# NANO112AN_v1 register map
File version: 1.0
Registers are 32-bit, read-write, reset 0x0 unless marked. A register's access mark holds for its fields unless they carry their own. Offsets are from the block's base; [hi:lo] are bit positions; {n}, {i} and the like mark numbered series; 'fields as' and 'values as' point back to an identical list.

## GCR — GCR Register Map
Base 0x50000000
0x00 PDID ro reset 0x110000 (reset mask 0xFFFF0000) — Part Device Identification Number Register
  [31:0] PDID — Part Device ID. This register reflects device part number code. Software can read this register to identify which device is used.
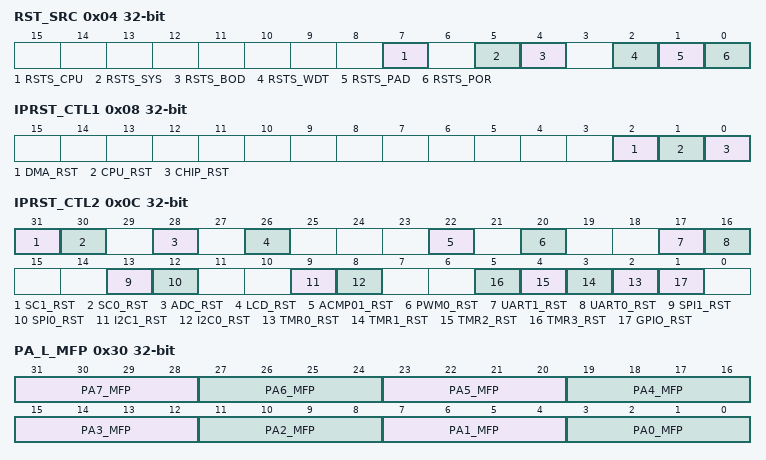
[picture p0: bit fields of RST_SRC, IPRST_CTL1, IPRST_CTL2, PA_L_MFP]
0x04 RST_SRC (reset mask 0xFFFFFF00) — System Reset Source Register
  [7] RSTS_CPU — The RSTS_CPU Flag Is Set by Hardware If Software Writes CPU_RST (IPRST_CTL1[1]) "1" to Rest Cortex-m0 Core and Flash Memory Controller (FMC). Note: This bit is cleared by writing 1 to it.
    0=No reset from CPU; 1=Cortex-M0 core and FMC are reset by software setting CPU_RST to 1
  [5] RSTS_SYS — The RSTS_SYS Flag Is Set by the "Reset Signal" From the Cortex_M0 Kernel to Indicate the Previous Reset Source. Note: This bit is cleared by writing 1 to it.
    0=No reset from Cortex_M0; 1=Cortex_M0 had issued the reset signal to reset the system by writing 1 to the bit SYSRESTREQ(AIRCR[2], Application Interrupt and Reset Control Register) in system control registers of Cortex_M0 kernel
  [4] RSTS_BOD — The RSTS_BOD Flag Is Set by the "Reset Signal" From the Brown-out-detected Module to Indicate the Previous Reset Source. Note: This bit is cleared by writing 1 to it.
    0=No reset from BOD; 1=Brown-out-Detected module had issued the reset signal to reset the system
  [2] RSTS_WDT — The RSTS_WDT Flag Is Set by the "Reset Signal" From the Watchdog Timer Module to Indicate the Previous Reset Source. Note: This bit is cleared by writing 1 to it.
    0=No reset from Watchdog Timer; 1=The Watchdog Timer module had issued the reset signal to reset the system
  [1] RSTS_PAD — The RSTS_PAD Flag Is Set by the "Reset Signal" From the /RESET Pin or Power Related Reset Sources to Indicate the Previous Reset Source. Note: This bit is cleared by writing 1 to it.
    0=No reset from nRESET pin; 1=The /RESET pin had issued the reset signal to reset the system
  [0] RSTS_POR — The RSTS_POR Flag Is Set by the "Reset Signal" From the Power-on Reset (POR) Module or Bit CHIP_RST (IPRSTC1[0]) to Indicate the Previous Reset Source. Note: This bit is cleared by writing 1 to it.
    0=No reset from POR or CHIP_RST; 1=Power-on Reset (POR) or CHIP_RST had issued the reset signal to reset the system
0x08 IPRST_CTL1 — Peripheral Reset Control Resister1
  [2] DMA_RST — DMA Controller Reset. This is a protected register. Please refer to open lock sequence to program it. Set this bit "1" will generate a reset signal to the DMA. SW needs to set this bit to low to release reset signal.
    0=Normal operation; 1=DMA IP reset
  [1] CPU_RST — Cortex-m0 Core One-shot Reset. This is a protected register. Please refer to open lock sequence to program it. Setting this bit will only reset the Cortex-M0 core and Flash Memory Controller (FMC), and this bit will automatically return to "0" after the 2 clock cycles
    0=Normal; 1=Reset Cortex-M0 core
  [0] CHIP_RST — Chip One-shot Reset. This is a protected register. Please refer to open lock sequence to program it. Setting this bit will reset the whole chip, including Cortex-M0 core and all peripherals like power-on reset and this bit will automatically return to "0" after the 2 clock cycles. The chip setting from flash will be also reloaded when chip one shot reset. Note: In the following conditions, chip setting from flash will be reloaded. Power-on Reset. Brown-out-Detected Reset. Low level on the nRESET pin. Set IPRST_CTL1[CHIP_RST]
    0=Normal; 1=Reset chip
0x0C IPRST_CTL2 — Peripheral Reset Control Resister2
  [31] SC1_RST — SmartCard1 Controller Reset
    0=SmartCard module normal operation; 1=SmartCard module reset
  [30] SC0_RST — SmartCard 0 Controller Reset
    values as SC1_RST
  [28] ADC_RST — ADC Controller Reset
    0=ADC module normal operation; 1=ADC module reset
  [26] LCD_RST — LCD Controller Reset
    0=LCD module normal operation; 1=LCD module reset
  [22] ACMP01_RST — Comparator Controller Reset
    0=Comparator module normal operation; 1=Comparator module reset
  [20] PWM0_RST — PWM0 Controller Reset
    0=PWM0 module normal operation; 1=PWM0 module reset
  [17] UART1_RST — UART1 Controller Reset
    0=UART1 module normal operation; 1=UART1 module reset
  [16] UART0_RST — UART0 Controller Reset
    0=UART0 module normal operation; 1=UART0 module reset
  [13] SPI1_RST — SPI1 Controller Reset
    0=SPI1 module normal operation; 1=SPI1 module reset
  [12] SPI0_RST — SPI0 Controller Reset
    0=SPI0 module normal operation; 1=SPI0 module reset
  [9] I2C1_RST — I2C1 Controller Reset
    0=I2C1 module normal operation; 1=I2C1 module reset
  [8] I2C0_RST — I2C0 Controller Reset
    0=I2C0 module normal operation; 1=I2C0 module reset
  [n+2] TMR{n}_RST (n=0..3) — Timer{n} Controller Reset
    0=Timer{n} module normal operation; 1=Timer{n} module reset
  [1] GPIO_RST — GPIO Controller Reset
    0=GPIO module normal operation; 1=GPIO module reset
0x20 TEMPCTL — Temperature Sensor Control Register
  [0] VTEMP_EN — Temperature Sensor Enable Control
    0=Temperature sensor function Disabled (default); 1=Temperature sensor function Enabled
0x30 PA_L_MFP — Port A Low Byte Multiple Function Control Register
  [31:28] PA7_MFP — PA.7 Pin Function Selection
  [27:24] PA6_MFP — PA.6 Pin Function Selection
  [23:20] PA5_MFP — PA.5 Pin Function Selection
  [19:16] PA4_MFP — PA.4 Pin Function Selection
  [15:12] PA3_MFP — PA.3 Pin Function Selection
  [11:8] PA2_MFP — PA.2 Pin Function Selection
  [7:4] PA1_MFP — PA.1 Pin Function Selection
  [3:0] PA0_MFP — PA.0 Pin Function Selection
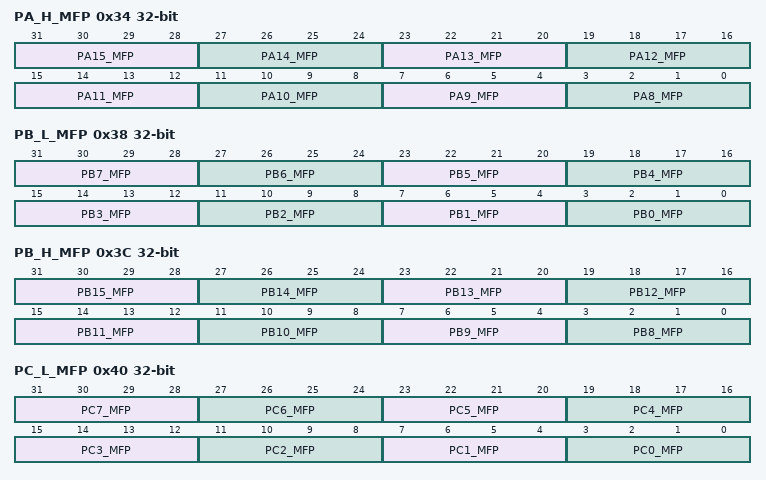
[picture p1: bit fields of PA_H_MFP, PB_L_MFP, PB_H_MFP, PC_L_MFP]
0x34 PA_H_MFP — Port A High Byte Multiple Function Control Register
  [31:28] PA15_MFP — PA.15 Pin Function Selection
  [27:24] PA14_MFP — PA.14 Pin Function Selection
  [23:20] PA13_MFP — PA.13 Pin Function Selection
  [19:16] PA12_MFP — PA.12 Pin Function Selection
  [15:12] PA11_MFP — PA.11 Pin Function Selection
  [11:8] PA10_MFP — PA.10 Pin Function Selection
  [7:4] PA9_MFP — PA.9 Pin Function Selection
  [3:0] PA8_MFP — PA.8 Pin Function Selection
0x38 PB_L_MFP — Port B Low Byte Multiple Function Control Register
  [31:28] PB7_MFP — PB.7 Pin Function Selection
  [27:24] PB6_MFP — PB.6 Pin Function Selection
  [23:20] PB5_MFP — PB.5 Pin Function Selection
  [19:16] PB4_MFP — PB.4 Pin Function Selection
  [15:12] PB3_MFP — PB.3 Pin Function Selection
  [11:8] PB2_MFP — PB.2 Pin Function Selection
  [7:4] PB1_MFP — PB.1 Pin Function Selection
  [3:0] PB0_MFP — PB.0 Pin Function Selection
0x3C PB_H_MFP — Port B High Byte Multiple Function Control Register
  [31:28] PB15_MFP — PB.15 Pin Function Selection
  [27:24] PB14_MFP — PB.14 Pin Function Selection
  [23:20] PB13_MFP — PB.13 Pin Function Selection
  [19:16] PB12_MFP — PB.12 Pin Function Selection
  [15:12] PB11_MFP — PB.11 Pin Function Selection
  [11:8] PB10_MFP — PB.10 Pin Function Selection
  [7:4] PB9_MFP — PB.9 Pin Function Selection
  [3:0] PB8_MFP — PB.8 Pin Function Selection
0x40 PC_L_MFP — Port C Low Byte Multiple Function Control Register
  [31:28] PC7_MFP — PC.7 Pin Function Selection
  [27:24] PC6_MFP — PC.6 Pin Fuction Selection
  [23:20] PC5_MFP — PC.5 Pin Function Selection
  [19:16] PC4_MFP — PC.4 Pin Function Selection
  [15:12] PC3_MFP — PC.3 Pin Function Selection
  [11:8] PC2_MFP — PC.2 Pin Function Selection
  [7:4] PC1_MFP — PC.1 Pin Function Selection
  [3:0] PC0_MFP — PC.0 Pin Function Selection
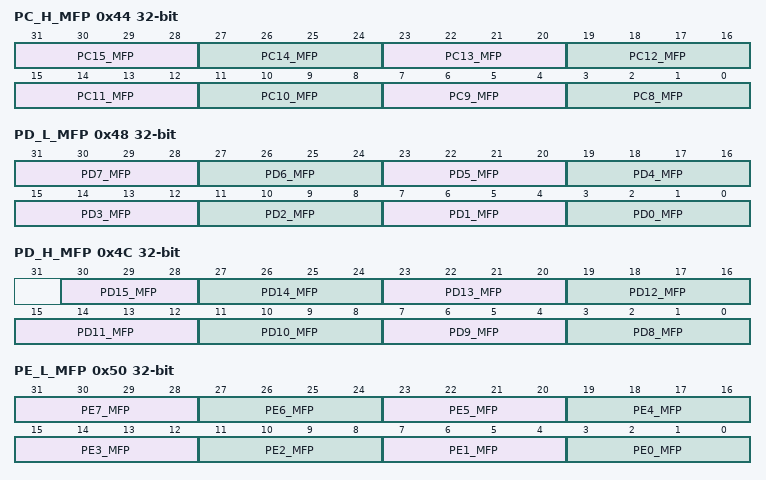
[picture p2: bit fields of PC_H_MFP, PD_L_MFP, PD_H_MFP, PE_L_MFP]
0x44 PC_H_MFP — Port C High Byte Multiple Function Control Register
  [31:28] PC15_MFP — PC.15 Pin Function Selection
  [27:24] PC14_MFP — PC.14 Pin Function Selection
  [23:20] PC13_MFP — PC.13 Pin Function Selection
  [19:16] PC12_MFP — PC.12 Pin Function Selection
  [15:12] PC11_MFP — PC.11 Pin Function Selection
  [11:8] PC10_MFP — PC.10 Pin Function Selection
  [7:4] PC9_MFP — PC.9 Pin Function Selection
  [3:0] PC8_MFP — PC.8 Pin Function Selection
0x48 PD_L_MFP — Port D Low Byte Multiple Function Control Register
  [31:28] PD7_MFP — PD.7 Pin Function Selection
  [27:24] PD6_MFP — PD.6 Pin Function Selection
  [23:20] PD5_MFP — PD.5 Pin Function Selection
  [19:16] PD4_MFP — PD.4 Pin Function Selection
  [15:12] PD3_MFP — PD.3 Pin Function Selection
  [11:8] PD2_MFP — PD.2 Pin Function Selection
  [7:4] PD1_MFP — PD.1 Pin Function Selection
  [3:0] PD0_MFP — PD.0 Pin Function Selection
0x4C PD_H_MFP — Port D High Byte Multiple Function Control Register
  [30:28] PD15_MFP — PD.15 Pin Function Selection
  [27:24] PD14_MFP — PD.14 Pin Function Selection
  [23:20] PD13_MFP — PD.13 Pin Function Selection
  [19:16] PD12_MFP — PD.12 Pin Function Selection
  [15:12] PD11_MFP — PD.11 Pin Function Selection
  [11:8] PD10_MFP — PD.10 Pin Function Selection
  [7:4] PD9_MFP — PD.9 Pin Function Selection
  [3:0] PD8_MFP — PD.8 Pin Function Selection
0x50 PE_L_MFP — Port E Low Byte Multiple Function Control Register
  [31:28] PE7_MFP — PE.7 Pin Function Selection
  [27:24] PE6_MFP — PE.6 Pin Function Selection
  [23:20] PE5_MFP — PE.5 Pin Function Selection
  [19:16] PE4_MFP — PE.4 Pin Function Selection
  [15:12] PE3_MFP — PE.3 Pin Function Selection
  [11:8] PE2_MFP — PE.2 Pin Function Selection
  [7:4] PE1_MFP — PE.1 Pin Function Selection
  [3:0] PE0_MFP — PE.0 Pin Function Selection
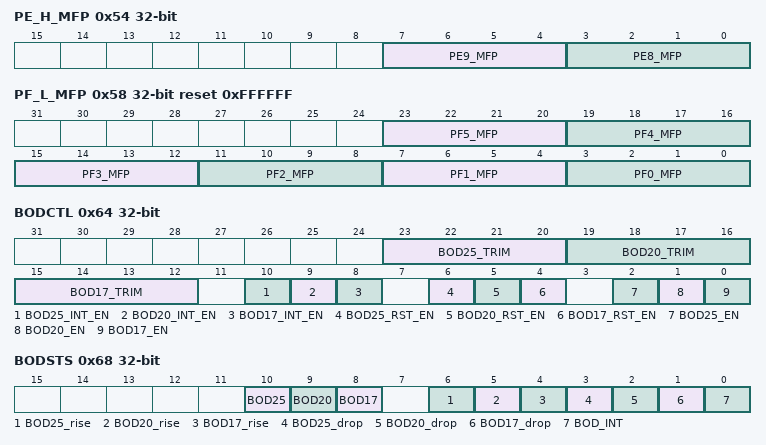
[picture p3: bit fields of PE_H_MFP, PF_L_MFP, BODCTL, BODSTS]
0x54 PE_H_MFP — Port E High Byte Multiple Function Control Register
  [7:4] PE9_MFP — PE.9 Pin Function Selection
  [3:0] PE8_MFP — PE.8 Pin Function Selection
0x58 PF_L_MFP reset 0xFFFFFF — Port F Low Byte Multiple Function Control Register
  [23:20] PF5_MFP — PF.5 Pin Function Selection
  [19:16] PF4_MFP — PF.4 Pin Function Selection
  [15:12] PF3_MFP — PF.3 Pin Function Selection
  [11:8] PF2_MFP — PF.2 Pin Function Selection
  [7:4] PF1_MFP — PF.1 Pin Function Selection
  [3:0] PF0_MFP — PF.0 Pin Function Selection
0x60 PORCTL — Power-On-reset Controller Register
  [15:0] POR_DIS_CODE — Power-on Reset Enable Control. This is a protected register. Please refer to open lock sequence to program it. When powered on, the POR circuit generates a reset signal to reset the whole chip function, but noise on the power may cause the POR active again. If setting the POR_DIS_CODE to 0x5AA5, the POR reset function will be disabled and the POR function will be active again when POR_DIS_CODE is set to another value or POR_DIS_CODE is reset by chip other reset functions, including: /RESET, Watchdog Timer reset, BOD reset, ICE reset command and the software-chip reset function
0x64 BODCTL (reset mask 0xFF000F00) — Brown-out Detector Controller Register
  [23:20] BOD25_TRIM — BOD 2.5 TRIM Value. This is a protected register. Please refer to open lock sequence to program it. This value is used to control BOD25 detect voltage level, nominal 2.5 V. Higher trim value, higher detection voltage.
  [19:16] BOD20_TRIM — BOD 2.0 TRIM Value. This is a protected register. Please refer to open lock sequence to program it. This value is used to control BOD20 detect voltage level, nominal 2.0 V. Higher trim value, higher detection voltage.
  [15:12] BOD17_TRIM — BOD 1.7 TRIM Value. This is a protected register. Please refer to open lock sequence to program it. This value is used to control BOD17 detect voltage level, nominal 1.7 V. Higher trim value, higher detection voltage.
  [10] BOD25_INT_EN — BOD 2.5 V Interrupt Enable Control. This is a protected register. Please refer to open lock sequence to program it.
    0=Interrupt does not issue when BOD25 occurs; 1=Interrupt issues when BOD25 occurs
  [9] BOD20_INT_EN — BOD 2.0 V Interrupt Enable Control
    0=Interrupt does not issue when BOD20 occurs; 1=Interrupt issues when BOD20 occurs
  [8] BOD17_INT_EN — BOD 1.7 V Interrupt Enable Control. This is a protected register. Please refer to open lock sequence to program it.
    0=Interrupt does not issue when BOD17 occurs; 1=Interrupt issues when BOD17 occurs
  [6] BOD25_RST_EN — BOD 2.5 V Reset Enable Control. This is a protected register. Please refer to open lock sequence to program it. The default value is set by flash controller user configuration register config0 bit[20:19]
    0=Reset does not issue when BOD25 occurs; 1=Reset issues when BOD25 occurs
  [5] BOD20_RST_EN — BOD 2.0 V Reset Enable Control. This is a protected register. Please refer to open lock sequence to program it. The default value is set by flash controller user configuration register config0 bit[20:19]
    0=Reset does not issue when BOD20 occurs; 1=Reset issues when BOD20 occurs
  [4] BOD17_RST_EN — BOD 1.7 V Reset Enable Control
    0=Reset does not issue when BOD17 occurs; 1=Reset issues when BOD17 occurs
  [2] BOD25_EN — Brown-out Detector 2.5 V Function Enable Control. This is a protected register. Please refer to open lock sequence to program it.
    0=Brown-out Detector 2.5 V function Disabled; 1=Brown-out Detector 2.5 V function Enabled
  [1] BOD20_EN — Brown-out Detector 2.0 V Function Enable Control. This is a protected register. Please refer to open lock sequence to program it. BOD20_EN is default on. If SW disables it, Brown-out Detector 2.0 V function is not disabled until chip enters Power-down mode. If system is not in Power-down mode, BOD20_EN will be enabled by hardware automatically.
    0=Brown-out Detector 2.0 V function Disabled; 1=Brown-out Detector 2.0 V function Enabled
  [0] BOD17_EN — Brown-out Detector 1.7V Function Enable Control
    0=Brown-out Detector 1.7V function Disabled; 1=Brown-out Detector 1.7V function Enabled
0x68 BODSTS ro — Brown-out Detector Status Register
  [10] BOD25 — Brown-out Detector 2.5V Status. This bit reflects the BOD25 status. BOD25 is high if detected voltage is higher than 2.5 V. BOD25 is low if detected voltage is lower than 2.5 V. Note: This bit is ready-only.
  [9] BOD20 — Brown-out Detector 2.0V Status. This bit reflects the BOD20 status. BOD20 is high if detected voltage is higher than 2.0 V. BOD20 is low if detected voltage is lower than 2.0 V. Note: This bit is ready-only.
  [8] BOD17 — Brown-out Detector 1.7V Status. This bit reflects the BOD17 status. BOD17 is high if detected voltage is higher than 1.7 V. BOD17 is low if detected voltage is lower than 1.7 V. Note: This bit is ready-only.
  [6] BOD25_rise — Brown-out Detector Higher Than 2.5V Status. Setting BOD25_rise high means once the detected voltage is higher than target detected voltage setting (2.5V). Software can write 1 to clear BOD25_rise.
  [5] BOD20_rise — Brown-out Detector Higher Than 2.0V Status. Setting BOD20_rise high means once the detected voltage is higher than target detected voltage setting (2.0V). Software can write 1 to clear BOD20_rise
  [4] BOD17_rise — Brown-out Detector Higher Than 1.7V Status. Setting BOD17_rise high means once the detected voltage is higher than target detected voltage setting (1.7V). Software can write 1 to clear BOD17_rise
  [3] BOD25_drop — Brown-out Detector Lower Than 2.5V Status. Setting BOD25_drop high means once the detected voltage is lower than target detected voltage setting (2.5V). Software can write 1 to clear BOD25_drop
  [2] BOD20_drop — Brown-out Detector Lower Than 2.0V Status. Setting BOD20_drop high means once the detected voltage is lower than target detected voltage setting (2.0V). Software can write 1 to clear BOD20_drop
  [1] BOD17_drop — Brown-out Detector Lower Than 1.7V Status. Setting BOD17_drop high means once the detected voltage is lower than target detected voltage setting (1.7V). Software can write 1 to clear BOD17_drop
  [0] BOD_INT — Brown-out Detector Interrupt Status. This bit is cleared by writing 1 to it.
    0=Brown-out Detector does not detect any voltage drift at VDD down through or up through the target detected voltage after interrupt is enabled; 1=When Brown-out Detector detects the VDD is dropped down through the target detected voltage or the VDD is raised up through the target detected voltage and Brown-out interrupt is enabled, this bit will be set to 1
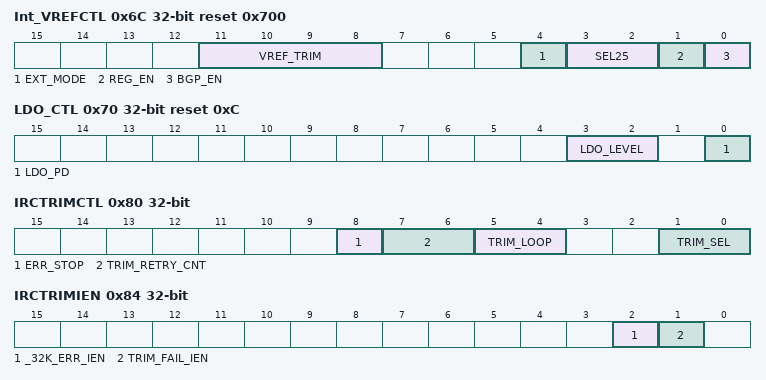
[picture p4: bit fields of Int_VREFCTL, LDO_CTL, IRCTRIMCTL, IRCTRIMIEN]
0x6C Int_VREFCTL reset 0x700 — Internal Voltage Reference Control Register
  [11:8] VREF_TRIM — Internal Voltage Reference Trim
  [4] EXT_MODE — Regulator External Mode. This is a protected register. Please refer to open lock sequence to program it. Users can output regulator output voltage in VREF pin if EXT_MODE is high.
    0=No connection with external VREF pin; 1=Connet to external VREF pin. Connect a 1uF to 10uF capacitor to AVSS will let internal voltage reference be more stable
  [3:2] SEL25 — Regulator Output Voltage Selection. Select internal reference voltage level. This is a protected register. Please refer to open lock sequence to program it.
    0=1.5V; 1=1.8V; 2=2.5V; 3=2.5V
  [1] REG_EN — Regulator Enable Control. Enable internal 1.5, 1.8V or 2.5V reference voltage. This is a protected register. Please refer to open lock sequence to program it.
    0=Disabled; 1=Enabled
  [0] BGP_EN — Band-gap Enable Control. This is a protected register. Please refer to open lock sequence to program it. Band-gap is the reference voltage of internal reference voltage. User must enable band-gap if want to enable internal 1.5, 1.8V or 2.5V reference voltage.
    0=Disabled; 1=Enabled
0x70 LDO_CTL reset 0xC — LDO Control Register
  [3:2] LDO_LEVEL — LDO Output Voltage Select. This is a protected register. Please refer to open lock sequence to program it.
    0=Reseved; 1=1.6V; 2=1.8V; 3=1.8V
  [0] LDO_PD — LDO Power Off. This is a protected register. Please refer to open lock sequence to program it. Set this bit high will off LDO and cause Chip in unexpected state. User must keep this bit low.
    0=LDO Enabled; 1=LDO Disabled
0x80 IRCTRIMCTL — HIRC Trim Control Register
  [8] ERR_STOP — Trim Stop When 32.768 KHz Error Detected. This bit is used to control if stop the HIRC trim operation when 32.768 kHz clock error is detected. If set this bit high and 32.768 kHz clock error detected, the status 32K_ERR_INT (IRCTRIMINT[2]) would be set high and HIRC trim operation was stopped. If this bit is low and 32.768 kHz clock error detected, the status 32K_ERR_INT (IRCTRIMINT[2]) would be set high and HIRC trim operation is continuously.
    0=Continue the HIRC trim operation even if 32.768 kHz clock error detected; 1=Stop the HIRC trim operation if 32.768 kHz clock error detected
  [7:6] TRIM_RETRY_CNT — Trim Value Update Limitation Count
  [5:4] TRIM_LOOP — Trim Calculation Loop
  [1:0] TRIM_SEL — Trim Frequency Selection
0x84 IRCTRIMIEN — HIRC Trim Interrupt Enable Register
  [2] _32K_ERR_IEN — 32.768 KHz Clock Error Interrupt Enable Control. This bit controls if CPU would get an interrupt while 32.768 kHz clock is inaccuracy during auto trim operation. If this bit is high, and 32K_ERR_INT (IRCTRIMINT[2]) is set during auto trim operation, an interrupt will be triggered to notify the 32.768 kHz clock frequency is inaccuracy.
    0=32K_ERR_INT (IRCTRIMINT[2]) status Disabled to trigger an interrupt to CPU; 1=32K_ERR_INT (IRCTRIMINT[2]) status Enabled to trigger an interrupt to CPU
  [1] TRIM_FAIL_IEN — Trim Failure Interrupt Enable Control. This bit controls if an interrupt will be triggered while HIRC trim value update limitation count reached and HIRC frequency still not locked on target frequency set by TRIM_SEL (IRCTRIMCTL[1:0]). If this bit is high and TRIM_FAIL_INT (IRCTRIMINT[1]) is set during auto trim operation, an interrupt will be triggered to notify that HIRC trim value update limitation count was reached.
    0=TRIM_FAIL_INT (IRCTRIMINT[1:0]) status Disabled to trigger an interrupt to CPU; 1=TRIM_FAIL_INT (IRCTRIMINT[1:0]) status Enabled to trigger an interrupt to CPU
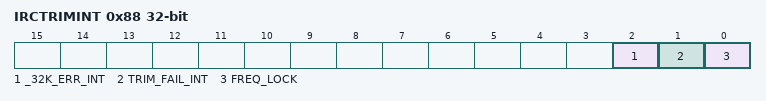
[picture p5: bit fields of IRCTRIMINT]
0x88 IRCTRIMINT — HIRC Trim Interrupt Status Register
  [2] _32K_ERR_INT — 32.768 KHz Clock Error Interrupt Status. This bit indicates that 32.768 kHz clock frequency is inaccuracy. Once this bit is set, the auto trim operation stopped and TRIM_SEL (IRCTRIMCTL[1:0]) will be cleared to 00 by hardware automatically. If this bit is set and 32K_ERR_IEN (IRCTRIMIEN[2]) is high, an interrupt will be triggered to notify the 32.768 kHz clock frequency is inaccuracy. Write 1 to clear this to zero.
    0=32.768 kHz clock frequency is accuracy; 1=32.768 kHz clock frequency is inaccuracy
  [1] TRIM_FAIL_INT — Trim Failure Interrupt Status. This bit indicates that HIRC trim value update limitation count reached and HIRC clock frequency still doesn't lock. Once this bit is set, the auto trim operation stopped and TRIM_SEL (IRCTRIMCTL[1:0]) will be cleared to 00 by hardware automatically. If this bit is set and TRIM_FAIL_IEN (IRCTRIMIEN[1]) is high, an interrupt will be triggered to notify that HIRC trim value update limitation count was reached. Write 1 to clear this to zero.
    0=Trim value update limitation count doesn't reach; 1=Trim value update limitation count reached and HIRC frequency still doesn't lock
  [0] FREQ_LOCK — HIRC Frequency Lock Status. This bit indicates the HIRC frequency lock. This is a status bit and doesn't trigger any interrupt.
0x100 RegLockAddr — Register Lock Key Address
  [0] RegUnLock — Protected Register Enable Control
    0=Protected register are Locked. Any write to the target register is ignored; 1=Protected registers are Unlocked
